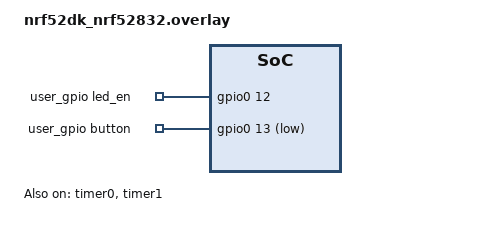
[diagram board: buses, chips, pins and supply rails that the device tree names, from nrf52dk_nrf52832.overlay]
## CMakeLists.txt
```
cmake_minimum_required(VERSION 3.20.0)
find_package(Zephyr REQUIRED HINTS $ENV{ZEPHYR_BASE})

project(nordic)

target_include_directories(app PRIVATE src src/drivers)

# Get all source and header files
file(GLOB_RECURSE SOURCES src/*.c src/drivers/*.c)
file(GLOB_RECURSE HEADERS src/*.h src/drivers/*.h)

# Add sources and header files to project
target_sources(app PRIVATE ${SOURCES})
target_sources(app PRIVATE ${HEADERS})
```

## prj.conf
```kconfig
#
# LOGGING
#
CONFIG_LOG=y

#
# PERIPHERALS
#
CONFIG_FPU=y
CONFIG_GPIO=y
CONFIG_I2C=y

#
# NRFX DRIVERS
#
CONFIG_NRFX_GPIOTE0=y
CONFIG_NRFX_PPI=y
CONFIG_NRFX_PWM1=y
CONFIG_NRFX_TIMER0=y
CONFIG_NRFX_TIMER1=y

#
# DEVICES
#

#
# SYSTEM
#
CONFIG_POWEROFF=y
```

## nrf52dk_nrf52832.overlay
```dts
// To get started, press Ctrl+Space to bring up the completion menu and view the available nodes.

// You can also use the buttons in the sidebar to perform actions on nodes.
// Actions currently available include:

// * Enabling / disabling the node
// * Adding the bus to a bus
// * Removing the node
// * Connecting ADC channels

// For more help, browse the DeviceTree documentation at https://docs.zephyrproject.org/latest/guides/dts/index.html
// You can also visit the nRF DeviceTree extension documentation at https://docs.nordicsemi.com/bundle/nrf-connect-vscode/page/guides/ncs_configure_app.html#devicetree-support-in-the-extension

&pwm_led0 {
	pwms = <&pwm0 0 PWM_KHZ(100) 0>;
};

/ {
	user_gpio: zephyr,user {
		led_en-gpios = <&gpio0 12 GPIO_PULL_DOWN>;
		button-gpios = <&gpio0 13 (GPIO_ACTIVE_LOW | GPIO_PULL_UP)>;
	};
};

&timer0 {
	status = "okay";
};

&timer1 {
	status = "okay";
};
```

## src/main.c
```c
/**
 * @file main.c
 * @author Ben Owen (ben@embeddedshark.com)
 * @brief Application entry file
 * 
 * @date 2024-10-20
 * 
 * @copyright Copyright (c) 2024
 * 
 */

#include "button.h"
#include "device.h"
#include "led.h"

#include <zephyr/kernel.h>
#include <zephyr/logging/log.h>
#include <nrfx_gpiote.h>

LOG_MODULE_REGISTER(MAIN, LOG_LEVEL_DBG);

/* Define task to handle button events */
#define BUTTON_THREAD_PRIORITY  4
K_THREAD_DEFINE(button_task_id, 1024, button_thread, NULL, NULL, NULL, BUTTON_THREAD_PRIORITY, 0, K_TICKS_FOREVER);  // Delay start to allow GPIO time to initialize

/**
 * @brief Application entry point
 * 
 * @return int 
 */
int main(void)
{
    /* Initialize peripherals */
    NRF_GPIO->DETECTMODE = GPIO_DETECTMODE_DETECTMODE_LDETECT;
    
    /* Get reset source */
    device_reset_src_t reset_src = device_get_reset_src();

    /* Initialize drivers */
    led_init();
    button_init();  // Needs to be last to enable all other wakeup sources before sleeping

    /* Start threads */
    k_thread_start(button_task_id);

    /* Put device to sleep if reset from flashing */
    if (reset_src == DEVICE_RESET_SRC_RESET_PIN)
    {
        device_poweroff();
    }

    return 0;
}
```

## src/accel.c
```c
/**
 * @file accel.c
 * @author Ben Owen (ben@embeddedshark.com)
 * @brief File containing setup for accelerometer
 * 
 * @date 2024-10-25
 * 
 * @copyright Copyright (c) 2024
 * 
 */

#include "accel.h"

#include "lis2dtw12.h"

#include <zephyr/device.h>
#include <zephyr/drivers/i2c.h>
#include <zephyr/logging/log.h>
#include <zephyr/sys/byteorder.h>
#include <zephyr/types.h>

LOG_MODULE_REGISTER(ACCEL, LOG_LEVEL_INF);

double accel_get_x(void)
{
    /* Read acceleration */
    int16_t accel_x = 0;
    lis2dtw12_reg_read(LIS2DTW12_OUT_X_L, &accel_x, 2);
    /* 14-bit = 0.244 mg/digit */
    double accel_x_converted = accel_x * 0.000244;

    return accel_x_converted;
}

double accel_get_y(void)
{
    /* Read acceleration */
    int16_t accel_y = 0;
    lis2dtw12_reg_read(LIS2DTW12_OUT_Y_L, &accel_y, 2);
    /* 14-bit = 0.244 mg/digit */
    double accel_y_converted = accel_y * 0.000244;

    return accel_y_converted;
}

double accel_get_z(void)
{
    /* Read acceleration */
    int16_t accel_z = 0;
    lis2dtw12_reg_read(LIS2DTW12_OUT_Z_L, &accel_z, 2);
    /* 14-bit = 0.244 mg/digit */
    double accel_z_converted = accel_z * 0.000244;

    return accel_z_converted;
}

int16_t accel_get_temp(void)
{
    /* Read temperature */
    int16_t temperature = 0;
    lis2dtw12_reg_read(LIS2DTW12_OUT_T_L, &temperature, 2);
    /* Convert temperature to celsius (integer, no decimals) */
    temperature >>= 8;  // 16 LSB per C, need to shift 4 additional since its 12-bit left-aligned
    temperature += 25;  // 0 LSB = 25 C
    
    return temperature;
}

void accel_init(void)
{
    /* Make sure device is responding */
    __ASSERT(lis2dtw12_get_device_id() == DEVICE_ID, "Acclerometer not responding on I2C bus");
    /* Initialize accelerometer with desired settings */
    lis2dtw12_init(CTRL1_ODR_25_HZ, CTRL1_MODE_HP, CTRL1_LP_MODE_2, CTRL6_BW_FILT_ODR_2, CTRL6_FS_2G, CTRL6_FDS, 0);
    /* Set INT1 pin configuration */
    lis2dtw12_reg_write(LIS2DTW12_CTRL4_INT1_PAD_CTRL, CTRL4_INT1_PAD_CTRL_INT1_WU);
    /* Set INT2 pin configuration */
    lis2dtw12_reg_write(LIS2DTW12_CTRL5_INT2_PAD_CTRL, CTRL5_INT2_PAD_CTRL_INT2_SLEEP_STATE | CTRL5_INT2_PAD_CTRL_INT2_SLEEP_CHG);
    /* Set wake up threshold */
    lis2dtw12_reg_write(LIS2DTW12_WAKE_UP_THS, WAKE_UP_THS_SLEEP_ON | (0b001000 & WAKE_UP_THS_WK_THS));  // should be 0.25 g
    /* Set wake up/sleep duration
        WAKE UP:
            At 25 Hz, each LSB = 0.04 seconds
            Maximum duration is 0b11 = 0.12 seconds
        SLEEP:
            At 25 Hz, each LSB = 20.48 seconds
            Maximum duration is 0b1111 ~= 300 seconds (5 minutes) */
    lis2dtw12_reg_write(LIS2DTW12_WAKE_UP_DUR, (0b01 & WAKE_UP_DUR_WAKE_DUR) | (0b1111 & WAKE_UP_DUR_SLEEP_DUR));  // should be 0.08 second wake up duration, 20.48 second sleep duration
    /* Set CTRL7 fields to enable interrupts and filter out gravity */
    lis2dtw12_reg_write(LIS2DTW12_CTRL7, CTRL7_INTERRUPTS_ENABLE | CTRL7_HP_REF_MODE);
    /* Allow device time to poll some data */
    k_msleep(100);
}
```

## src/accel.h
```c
/**
 * @file accel.h
 * @author Ben Owen (ben@embeddedshark.com)
 * @brief Header file for accel.c
 * 
 * @date 2024-10-25
 * 
 * @copyright Copyright (c) 2024 Embedded Shark, LLC
 * 
 */

#ifndef __ACCEL_H__
#define __ACCEL_H__

#include "stdint.h"

/**
 * FUNCTION DECLARATIONS
 */

/**
 * @brief Get acceleration in X-axis
 * 
 * @return double accleration (g)
 */
double accel_get_x(void);

/**
 * @brief Get acceleration in Y-axis
 * 
 * @return double accleration (g)
 */
double accel_get_y(void);

/**
 * @brief Get acceleration in Z-axis
 * 
 * @return double accleration (g)
 */
double accel_get_z(void);

/**
 * @brief Get temperature
 * 
 * @return int16_t temperature (celsius)
 */
int16_t accel_get_temp(void);

/**
 * @brief Initialize accelerometer
 * 
 */
void accel_init(void);

#endif  /* __ACCEL_H__ */
```

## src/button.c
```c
/**
 * @file button.c
 * @author your name (you@domain.com)
 * @brief File containing interface button logic
 * 
 * @date 2024-10-20
 * 
 * @copyright Copyright (c) 2024
 * 
 */

#include "button.h"

#include "device.h"
#include "led.h"

#include <zephyr/drivers/gpio.h>
#include <zephyr/kernel.h>
#include <zephyr/logging/log.h>

LOG_MODULE_REGISTER(BUTTON, LOG_LEVEL_INF);

/* GPIO */
static const struct gpio_dt_spec _button_dt = GPIO_DT_SPEC_GET(DT_NODELABEL(user_gpio), button_gpios);

const struct gpio_dt_spec * button_get_dt_spec(void)
{
    return &_button_dt;
}

void button_thread(void)
{
    /* The button buffer works by shifting left and ORing the button state
        If the buffer is all 1s, then a long press occurred
        If the buffer is some 1s followed by a 0, then a press was released */
    uint32_t button_buffer = 0;

    while (1)
    {
        /* Place button state into buffer */
        button_buffer = (button_buffer << 1) | gpio_pin_get_dt(&_button_dt);
        /* Check for button events */
        if (button_buffer == 0x7FFFFFFF)
        {
            /* Long press occurred
                We use 0x7FFFFFFF so that it won't constantly detect long presses if still held */
            LOG_DBG("Long press");
            if (device_get_state() == DEVICE_STATE_POWEROFF)
            {
                /* Wake up device */
                device_wakeup();
            }
            else if (device_get_state() == DEVICE_STATE_RUN)
            {
                /* Power off device if running */
                device_poweroff();
            }
        }
        else if (button_buffer == 0xFFFFFFFE)
        {
            /* Long press released */
            LOG_DBG("Long press released");
        }
        else if ((button_buffer & 0x3) == 0x2)
        {
            /* Short press released */
            LOG_DBG("Short press released");
            if (device_get_state() == DEVICE_STATE_POWEROFF)
            {
                /* Button not held long enough, go back to sleep */
                device_poweroff();
            }
            else if (device_get_state() == DEVICE_STATE_RUN)
            {
                /* Toggle LED pattern */
                led_toggle_pattern();
            }
        }

        /* Delay until next poll interval */
        k_msleep(1000 / BUTTON_POLL_HZ);
    }
}

void button_init()
{
    int err;

    /* GPIO config */
    /* Initialize GPIO */
	__ASSERT(device_is_ready(_button_dt.port), "Button port not ready");
    /* Configure button as input pin */
	err = gpio_pin_configure_dt(&_button_dt, GPIO_INPUT);
	__ASSERT(err == 0, "Error configuring button as input");
}
```

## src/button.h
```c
/**
 * @file button.h
 * @author Ben Owen (ben@embeddedshark.com)
 * @brief Header file for button.c
 * 
 * @date 2024-10-20
 * 
 * @copyright Copyright (c) 2024
 * 
 */

#ifndef __BUTTON_H__
#define __BUTTON_H__

#define BUTTON_GPIOTE_INSTANCE      0
#define BUTTON_TIMER_INSTANCE       1

#define BUTTON_POLL_HZ              20

/**
 * @brief Get the button GPIO DT spec
 * 
 * @return struct gpio_dt_spec* 
 */
const struct gpio_dt_spec * button_get_dt_spec(void);

/**
 * @brief This thread reads button inputs and handles short/long presses
 * 
 */
void button_thread(void);

/**
 * @brief Initialize all peripherals for interface button
 * 
 */
void button_init(void);

#endif  /* __BUTTON_H__ */
```

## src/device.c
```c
/**
 * @file device.c
 * @author Ben Owen (ben@embeddedshark.com)
 * @brief File containing global device-level functions
 *          Also contains global device-level state variables
 * 
 * @date 2024-10-21
 * 
 * @copyright Copyright (c) 2024
 * 
 */

#include "device.h"

#include "button.h"
#include "led.h"

#include <zephyr/drivers/gpio.h>
#include <zephyr/kernel.h>
#include <zephyr/logging/log.h>
#include <zephyr/sys/poweroff.h>

LOG_MODULE_REGISTER(DEVICE, LOG_LEVEL_INF);

/**
 * LOCAL VARIABLES
 */

static device_state_t _device_state;

/**
 * FUNCTION DEFINITIONS
 */

device_state_t device_get_state(void)
{
    return _device_state;
}

void device_set_state(device_state_t new_state)
{
    _device_state = new_state;
}

void device_wakeup(void)
{
    /* Set device state */
    device_set_state(DEVICE_STATE_RUN);
    /* Set boot LED pattern */
    led_set_pattern(LED_PATTERN_PULSE);
}

void device_poweroff()
{
    int err;

    /* Change device state */
    device_set_state(DEVICE_STATE_POWEROFF);
    /* Clear LED */
    led_set_pattern(LED_PATTERN_OFF);
    /* Wait until button released */
    while (gpio_pin_get_dt(button_get_dt_spec()));
    k_msleep(250);  // delay a small period for button bouncing
    /* Configure interrupt for button (wakeup source) */
    err = gpio_pin_interrupt_configure_dt(button_get_dt_spec(), GPIO_INT_LEVEL_ACTIVE);
    __ASSERT(err == 0, "Error changing button interrupt");
    /* Clear LATCH register */
    NRF_GPIO->LATCH = NRF_GPIO->LATCH;
    /* Put microcontroller to sleep */
    LOG_WRN("Powering device off");
    sys_poweroff();
}

device_reset_src_t device_get_reset_src(void)
{
    /* Get reset source */
    uint32_t reset_src = NRF_POWER->RESETREAS;
    /* Clear reset source register */
    NRF_POWER->RESETREAS = 0xFFFFFFFF;

    /* Determine reset reason */
    if (reset_src & POWER_RESETREAS_OFF_Msk)
    {
        return DEVICE_RESET_SRC_GPIO_WAKEUP;
    }
    else if (reset_src & POWER_RESETREAS_LOCKUP_Msk)
    {
        return DEVICE_RESET_SRC_CPU_LOCKUP;
    }
    else if (reset_src & POWER_RESETREAS_SREQ_Msk)
    {
        return DEVICE_RESET_SRC_SOFT_RESET;
    }
    else if (reset_src & POWER_RESETREAS_DOG_Msk)
    {
        return DEVICE_RESET_SRC_WATCHDOG;
    }
    else if (reset_src & POWER_RESETREAS_RESETPIN_Msk)
    {
        return DEVICE_RESET_SRC_RESET_PIN;
    }
    else
    {
        return DEVICE_RESET_SRC_OTHER;
    }
}
```

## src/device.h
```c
/**
 * @file device.h
 * @author Ben Owen (ben@embeddedshark.com)
 * @brief Header file for device.c
 * 
 * @date 2024-10-21
 * 
 * @copyright Copyright (c) 2024
 * 
 */

#ifndef __DEVICE_H__
#define __DEVICE_H__

#include <zephyr/drivers/gpio.h>

/* ENUMERATION DEFINITIONS */

typedef enum
{
    DEVICE_STATE_POWEROFF,
    DEVICE_STATE_WAKEUP,
    DEVICE_STATE_RUN,
}
device_state_t;

typedef enum
{
    DEVICE_RESET_SRC_GPIO_WAKEUP,
    DEVICE_RESET_SRC_CPU_LOCKUP,
    DEVICE_RESET_SRC_SOFT_RESET,
    DEVICE_RESET_SRC_WATCHDOG,
    DEVICE_RESET_SRC_RESET_PIN,
    DEVICE_RESET_SRC_OTHER,
}
device_reset_src_t;

/**
 * FUNCTION DECLARATIONS
 */

/**
 * @brief Get the device state
 * 
 */
device_state_t device_get_state(void);

/**
 * @brief Change the device state
 * 
 * @param new_state 
 */
void device_set_state(device_state_t new_state);

/**
 * @brief Device initialization when waking from sleep
 * 
 */
void device_wakeup(void);

/**
 * @brief Turn the device off
 *          Handles cleanup before shutting off
 * 
 */
void device_poweroff();

/**
 * @brief Get the device wakeup reason
 * 
 * @return device_reset_src_t 
 */
device_reset_src_t device_get_reset_src(void);

#endif  /* __DEVICE_H__ */
```

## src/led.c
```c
/**
 * @file led.c
 * @author Ben Owen (ben@embeddedshark.com)
 * @brief File to initialize and change LED blink modes
 * 
 * @date 2024-10-20
 * 
 * @copyright Copyright (c) 2024
 * 
 */

#include "led.h"

#include <nrfx_gpiote.h>
#include <nrfx_ppi.h>
#include <nrfx_pwm.h>
#include <nrfx_timer.h>

#include <zephyr/logging/log.h>

#if (LED_TIMER_INSTANCE == 0)
#define LED_TIMER_IRQN       TIMER0_IRQn
#elif (LED_TIMER_INSTANCE == 1)
#define LED_TIMER_IRQN       TIMER1_IRQn
#elif (LED_TIMER_INSTANCE == 2)
#define LED_TIMER_IRQN       TIMER2_IRQn
#elif (LED_TIMER_INSTANCE == 3)
#define LED_TIMER_IRQN       TIMER3_IRQn
#elif (LED_TIMER_INSTANCE == 4)
#define LED_TIMER_IRQN       TIMER4_IRQn
#endif

LOG_MODULE_REGISTER(LED, LOG_LEVEL_INF);

/**
 * @brief Pattern for constant max brightness
 * 
 */
nrf_pwm_values_common_t _pwm_pattern_on[] =
{
    100,
};
nrf_pwm_sequence_t _pwm_seq_on =
{
    .values = { _pwm_pattern_on },
    .length = NRFX_ARRAY_SIZE(_pwm_pattern_on),
    .repeats = 10,  // 10 ticks per value
    .end_delay = 0  // no delay between repeats
};

/**
 * @brief Pattern for constant medium brightness
 * 
 */
nrf_pwm_values_common_t _pwm_pattern_mid[] =
{
    600,
};
nrf_pwm_sequence_t _pwm_seq_mid =
{
    .values = { _pwm_pattern_mid },
    .length = NRFX_ARRAY_SIZE(_pwm_pattern_mid),
    .repeats = 10,  // 10 ticks per value
    .end_delay = 0  // no delay between repeats
};

/**
 * @brief Pattern for constant low brightness
 * 
 */
nrf_pwm_values_common_t _pwm_pattern_dim[] =
{
    1000,
};
nrf_pwm_sequence_t _pwm_seq_dim =
{
    .values = { _pwm_pattern_dim },
    .length = NRFX_ARRAY_SIZE(_pwm_pattern_dim),
    .repeats = 10,  // 10 ticks per value
    .end_delay = 0  // no delay between repeats
};

/**
 * @brief Pattern for dim blinking
 * 
 */
nrf_pwm_values_common_t _pwm_pattern_dim_blink[] =
{
    600,  1000, 1000, 1000, 1000, 1000, 1000, 1000, 1000, 600,
    1000, 1000, 1000, 1000, 1000, 1000, 1000, 1000, 1000, 1000,
    1000, 1000, 1000, 1000, 1000, 1000, 1000, 1000, 1000, 1000,
    1000, 1000, 1000, 1000, 1000, 1000, 1000, 1000, 1000, 1000,
    1000, 1000, 1000, 1000, 1000, 1000, 1000, 1000, 1000, 1000,
    1000, 1000, 1000, 1000, 1000, 1000, 1000, 1000, 1000, 1000,
    1000, 1000, 1000, 1000, 1000, 1000, 1000, 1000, 1000, 1000,
    1000, 1000, 1000, 1000, 1000, 1000, 1000, 1000, 1000, 1000,
    1000, 1000, 1000, 1000, 1000, 1000, 1000, 1000, 1000, 1000,
    1000, 1000, 1000, 1000, 1000, 1000, 1000, 1000, 1000, 1000,
};
nrf_pwm_sequence_t _pwm_seq_dim_blink =
{
    .values = { _pwm_pattern_dim_blink },
    .length = NRFX_ARRAY_SIZE(_pwm_pattern_dim_blink),
    .repeats = 10,  // 10 ticks per value
    .end_delay = 0  // no delay between repeats
};

/**
 * @brief Pattern for pulsing
 * 
 */
nrf_pwm_values_common_t _pwm_pattern_pulse[] =
{
    990,  980,  970,  960,  950,  940,  930,  920,  910,  900,
    890,  880,  870,  860,  850,  840,  830,  820,  810,  800,
    790,  780,  770,  760,  750,  740,  730,  720,  710,  700,
    690,  680,  670,  660,  650,  640,  630,  620,  610,  600,
    590,  580,  570,  560,  550,  540,  530,  520,  510,  500,
    500,  500,  500,  500,  500,  500,  500,  500,  500,  500,
    500,  510,  520,  530,  540,  550,  560,  570,  580,  590,
    600,  610,  620,  630,  640,  650,  660,  670,  680,  690,
    700,  710,  720,  730,  740,  750,  760,  770,  780,  790,
    800,  810,  820,  830,  840,  850,  860,  870,  880,  890,
    900,  910,  920,  930,  940,  950,  960,  970,  980,  990,
    1000, 1000, 1000, 1000, 1000, 1000, 1000, 1000, 1000, 1000,
};
nrf_pwm_sequence_t _pwm_seq_pulse =
{
    .values = { _pwm_pattern_pulse },
    .length = NRFX_ARRAY_SIZE(_pwm_pattern_pulse),
    .repeats = 25,  // 10 ticks per value
    .end_delay = 1000  // no delay between repeats
};

/* GPIO */
static nrfx_gpiote_t _gpiote = NRFX_GPIOTE_INSTANCE(LED_GPIOTE_INSTANCE);
#define LED_EN_PIN DT_GPIO_PIN(DT_NODELABEL(user_gpio), led_en_gpios)

/* Timer */
static nrfx_timer_t _timer_led = NRFX_TIMER_INSTANCE(LED_TIMER_INSTANCE);

/* PPI */
nrf_ppi_channel_t _ppi_first_blink_start_ch;
nrf_ppi_channel_t _ppi_first_blink_end_ch;
nrf_ppi_channel_t _ppi_second_blink_start_ch;
nrf_ppi_channel_t _ppi_second_blink_end_ch;

/* PWM */
static nrfx_pwm_t _pwm_led = NRFX_PWM_INSTANCE(LED_PWM_INSTANCE);
#define LED_PWM_PIN 17

/* Other locals */
led_pattern_t _current_pattern;

void led_init(void)
{
    nrfx_err_t err;

    /* GPIO config */
    /* Initialize GPIO */
    err = nrfx_gpiote_init(&_gpiote, NRFX_GPIOTE_DEFAULT_CONFIG_IRQ_PRIORITY);
    NRFX_ASSERT(err == NRFX_SUCCESS);
    /* Generate output configurations */
    nrfx_gpiote_output_config_t _led_en_config = NRFX_GPIOTE_DEFAULT_OUTPUT_CONFIG;
    /* Allocate GPIOTE channels for tasks */
    uint8_t _gpiote_led_en_ch;
    err = nrfx_gpiote_channel_alloc(&_gpiote, &_gpiote_led_en_ch);
    NRFX_ASSERT(err == NRFX_SUCCESS);
    /* Create tasks */
    nrfx_gpiote_task_config_t _led_en_task =
    {
        .task_ch = _gpiote_led_en_ch,
        .polarity = NRF_GPIOTE_POLARITY_TOGGLE,
        .init_val = NRF_GPIOTE_INITIAL_VALUE_LOW,
    };
    /* Configure LED enable pin with defined configurations */
    err = nrfx_gpiote_output_configure(&_gpiote, LED_EN_PIN, &_led_en_config, &_led_en_task);
    NRFX_ASSERT(err == NRFX_SUCCESS);
    /* Enable GPIOTE task */
    nrfx_gpiote_out_task_enable(&_gpiote, LED_EN_PIN);

    /* Timer config */
    /* Configure timer parameters */
    nrfx_timer_config_t _timer_led_config =
    {
        .frequency          = NRFX_MHZ_TO_HZ(1),
        .mode               = NRF_TIMER_MODE_TIMER,
        .bit_width          = NRF_TIMER_BIT_WIDTH_32,
        .interrupt_priority = NRFX_TIMER_DEFAULT_CONFIG_IRQ_PRIORITY,
        .p_context          = NULL,
    };
    /* Initialize timer */
    err = nrfx_timer_init(&_timer_led, &_timer_led_config, NULL);
    NRFX_ASSERT(err == NRFX_SUCCESS);
    /* Needed to handle timer compare interrupts */
    IRQ_CONNECT(LED_TIMER_IRQN, IRQ_PRIO_LOWEST, NRFX_TIMER_INST_HANDLER_GET(LED_TIMER_INSTANCE), NULL, 0);

    /* PWM config */
    /* Initialize PWM */
    nrfx_pwm_config_t config = NRFX_PWM_DEFAULT_CONFIG(LED_PWM_PIN, NRF_PWM_PIN_NOT_CONNECTED, NRF_PWM_PIN_NOT_CONNECTED, NRF_PWM_PIN_NOT_CONNECTED);
    err = nrfx_pwm_init(&_pwm_led, &config, NULL, &_pwm_led);
    NRFX_ASSERT(err == NRFX_SUCCESS);
    /* Handle PWM interrupt */
    IRQ_CONNECT(NRFX_IRQ_NUMBER_GET(NRF_PWM_INST_GET(LED_PWM_INSTANCE)), IRQ_PRIO_LOWEST, NRFX_PWM_INST_HANDLER_GET(LED_PWM_INSTANCE), 0, 0);

    /* PPI config */
    /* Allocate PPI channels */
    err = nrfx_ppi_channel_alloc(&_ppi_first_blink_start_ch);
    NRFX_ASSERT(err == NRFX_SUCCESS);
    err = nrfx_ppi_channel_alloc(&_ppi_first_blink_end_ch);
    NRFX_ASSERT(err == NRFX_SUCCESS);
    err = nrfx_ppi_channel_alloc(&_ppi_second_blink_start_ch);
    NRFX_ASSERT(err == NRFX_SUCCESS);
    err = nrfx_ppi_channel_alloc(&_ppi_second_blink_end_ch);
    NRFX_ASSERT(err == NRFX_SUCCESS);
}

void led_set_pattern(led_pattern_t pattern)
{
    nrfx_err_t err;
    /* Disable LED driver while setting up new pattern */
    nrfx_gpiote_clr_task_trigger(&_gpiote, LED_EN_PIN);
    /* Disable timer */
    nrfx_timer_disable(&_timer_led);
    nrfx_timer_clear(&_timer_led);
    /* Disable PPI channels */
    err = nrfx_ppi_channel_disable(_ppi_first_blink_start_ch);
    NRFX_ASSERT(err == NRFX_SUCCESS);
    err = nrfx_ppi_channel_disable(_ppi_first_blink_end_ch);
    NRFX_ASSERT(err == NRFX_SUCCESS);
    err = nrfx_ppi_channel_disable(_ppi_second_blink_start_ch);
    NRFX_ASSERT(err == NRFX_SUCCESS);
    err = nrfx_ppi_channel_disable(_ppi_second_blink_end_ch);
    NRFX_ASSERT(err == NRFX_SUCCESS);
    /* Disable PWM sequence */
    nrfx_pwm_stop(&_pwm_led, true);
    /* Store new pattern */
    _current_pattern = pattern;

    /* Set up pattern */
    switch (pattern)
    {
        case (LED_PATTERN_BRIGHT_BLINK):
        {
            /* Pattern is 2 quick blinks, otherwise off */
            /* Set timer compare channels */
            nrfx_timer_compare(&_timer_led, NRF_TIMER_CC_CHANNEL0, nrfx_timer_ms_to_ticks(&_timer_led, 10), false);
            nrfx_timer_compare(&_timer_led, NRF_TIMER_CC_CHANNEL1, nrfx_timer_ms_to_ticks(&_timer_led, 90), false);
            nrfx_timer_compare(&_timer_led, NRF_TIMER_CC_CHANNEL2, nrfx_timer_ms_to_ticks(&_timer_led, 100), false);
            nrfx_timer_extended_compare(&_timer_led, NRF_TIMER_CC_CHANNEL3, nrfx_timer_ms_to_ticks(&_timer_led, 1000), NRF_TIMER_SHORT_COMPARE3_CLEAR_MASK, false);
            /* Assign PPI channels to set/clear LED enable pin */
            err = nrfx_ppi_channel_assign(_ppi_first_blink_start_ch, nrfx_timer_event_address_get(&_timer_led, NRF_TIMER_EVENT_COMPARE3), nrfx_gpiote_set_task_address_get(&_gpiote, LED_EN_PIN));
            NRFX_ASSERT(err == NRFX_SUCCESS);
            err = nrfx_ppi_channel_assign(_ppi_first_blink_end_ch, nrfx_timer_event_address_get(&_timer_led, NRF_TIMER_EVENT_COMPARE0), nrfx_gpiote_clr_task_address_get(&_gpiote, LED_EN_PIN));
            NRFX_ASSERT(err == NRFX_SUCCESS);
            err = nrfx_ppi_channel_assign(_ppi_second_blink_start_ch, nrfx_timer_event_address_get(&_timer_led, NRF_TIMER_EVENT_COMPARE1), nrfx_gpiote_set_task_address_get(&_gpiote, LED_EN_PIN));
            NRFX_ASSERT(err == NRFX_SUCCESS);
            err = nrfx_ppi_channel_assign(_ppi_second_blink_end_ch, nrfx_timer_event_address_get(&_timer_led, NRF_TIMER_EVENT_COMPARE2), nrfx_gpiote_clr_task_address_get(&_gpiote, LED_EN_PIN));
            NRFX_ASSERT(err == NRFX_SUCCESS);
            /* Enable PPI channels */
            err = nrfx_ppi_channel_enable(_ppi_first_blink_start_ch);
            NRFX_ASSERT(err == NRFX_SUCCESS);
            err = nrfx_ppi_channel_enable(_ppi_first_blink_end_ch);
            NRFX_ASSERT(err == NRFX_SUCCESS);
            err = nrfx_ppi_channel_enable(_ppi_second_blink_start_ch);
            NRFX_ASSERT(err == NRFX_SUCCESS);
            err = nrfx_ppi_channel_enable(_ppi_second_blink_end_ch);
            NRFX_ASSERT(err == NRFX_SUCCESS);
            /* Set PWM sequence to max brightness (will control blinks with enable GPIO) */
            nrfx_pwm_simple_playback(&_pwm_led, &_pwm_seq_on, 1, NRFX_PWM_FLAG_LOOP);
            /* Start timer */
            nrfx_timer_enable(&_timer_led);
            break;
        }

        case (LED_PATTERN_DIM_BLINK):
        {
            /* Pattern is 2 quick blinks, otherwise dim */
            /* Enable LED driver constantly (PWM pattern will handle blinks) */
            nrfx_gpiote_set_task_trigger(&_gpiote, LED_EN_PIN);
            /* Set PWM sequence to dim blink pattern */
            nrfx_pwm_simple_playback(&_pwm_led, &_pwm_seq_dim_blink, 1, NRFX_PWM_FLAG_LOOP);
            break;
        }

        case (LED_PATTERN_BRIGHT_SOLID):
        {
            /* Pattern is solid bright */
            /* Enable LED driver constantly (PWM pattern will handle brightness) */
            nrfx_gpiote_set_task_trigger(&_gpiote, LED_EN_PIN);
            /* Set PWM sequence to bright solid pattern */
            nrfx_pwm_simple_playback(&_pwm_led, &_pwm_seq_mid, 1, NRFX_PWM_FLAG_LOOP);
            break;
        }

        case (LED_PATTERN_DIM_SOLID):
        {
            /* Pattern is solid dim */
            /* Enable LED driver constantly (PWM pattern will handle brightness) */
            nrfx_gpiote_set_task_trigger(&_gpiote, LED_EN_PIN);
            /* Set PWM sequence to dim solid pattern */
            nrfx_pwm_simple_playback(&_pwm_led, &_pwm_seq_dim, 1, NRFX_PWM_FLAG_LOOP);
            break;
        }

        case (LED_PATTERN_PULSE):
        {
            /* Pattern is pulse from dim to bright to dim */
            /* Enable LED driver constantly (PWM pattern will handle pulse) */
            nrfx_gpiote_set_task_trigger(&_gpiote, LED_EN_PIN);
            /* Set PWM sequence to pulse pattern */
            nrfx_pwm_simple_playback(&_pwm_led, &_pwm_seq_pulse, 1, NRFX_PWM_FLAG_LOOP);
            break;
        }

        case (LED_PATTERN_OFF):
        {
            /* Pattern is off */
            /* Disable LED driver */
            nrfx_gpiote_clr_task_trigger(&_gpiote, LED_EN_PIN);
            // /* Set PWM sequence to blink pattern */
            // nrfx_pwm_simple_playback(&_pwm_led, &_pwm_seq_mid, 1, NRFX_PWM_FLAG_LOOP);
            break;
        }

        default:
        {
            /* Invalid pattern */
            NRFX_ASSERT(0);
            break;
        }
    }
}

void led_toggle_pattern(void)
{
    _current_pattern = (_current_pattern + 1) % LED_PATTERN_NUM_PATTERNS;
    led_set_pattern(_current_pattern);
}
```

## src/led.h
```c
/**
 * @file led.h
 * @author Ben Owen (ben@embeddedshark.com)
 * @brief Header file for led.c
 * 
 * @date 2024-10-20
 * 
 * @copyright Copyright (c) 2024
 * 
 */

#ifndef __LED_H__
#define __LED_H__

#define LED_GPIOTE_INSTANCE 0
#define LED_PWM_INSTANCE    1
#define LED_TIMER_INSTANCE  0

typedef enum
{
    LED_PATTERN_BRIGHT_BLINK    = 0,
    LED_PATTERN_DIM_BLINK       = 1,
    LED_PATTERN_BRIGHT_SOLID    = 2,
    LED_PATTERN_DIM_SOLID       = 3,
    LED_PATTERN_PULSE           = 4,
    LED_PATTERN_NUM_PATTERNS,   // TOTAL NUMBER OF PATTERNS TO CYCLE
    LED_PATTERN_OFF,            // WILL NOT CYCLE TO OFF
}
led_pattern_t;

#endif  /* __LED_H__ */

/**
 * @brief Initialize all peripherals for LED control
 * 
 */
void led_init(void);

/**
 * @brief Set blink pattern of LED
 * 
 * @param pattern 
 */
void led_set_pattern(led_pattern_t pattern);

/**
 * @brief Toggle blink pattern (cycle through all patterns)
 * 
 */
void led_toggle_pattern(void);
```

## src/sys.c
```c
/**
 * @file sys.c
 * @author Ben Owen (ben@embeddedshark.com)
 * @brief File containing global system-level functions
 *          Also contains global system-level state variables
 * 
 * @date 2024-10-21
 * 
 * @copyright Copyright (c) 2024
 * 
 */

#include "sys.h"

#include "button.h"
#include "led.h"

#include <nrfx_gpiote.h>
#include <nrfx_timer.h>

#include <zephyr/drivers/gpio.h>
#include <zephyr/kernel.h>
#include <zephyr/logging/log.h>
#include <zephyr/sys/poweroff.h>

LOG_MODULE_REGISTER(SYS, LOG_LEVEL_INF);

/**
 * LOCAL VARIABLES
 */

sys_state_t sys_state = SYS_STATE_POWEROFF;

/**
 * FUNCTION DEFINITIONS
 */

void sys_power_off(const struct gpio_dt_spec * button_dt)
{
    nrfx_err_t err;

    // TODO: Turn off accelerometer - setting CTRL1 to 0x0000 will put device into power-down mode
    /* Clear LED */
    led_set_pattern(LED_PATTERN_OFF);
    /* Wait until button released */
    while (gpio_pin_get_dt(button_dt));
    k_msleep(250);  // delay a small period for button bouncing
    /* Configure interrupt for button (wakeup source) */
    err = gpio_pin_interrupt_configure_dt(button_dt, GPIO_INT_LEVEL_ACTIVE);
    NRFX_ASSERT(err == 0);
    /* Put microcontroller to sleep */
    LOG_WRN("Powering system off");
    sys_poweroff();
}

sys_reset_src_t sys_get_reset_src(void)
{
    /* Get reset source */
    uint32_t reset_src = NRF_POWER->RESETREAS;
    /* Clear reset source register */
    NRF_POWER->RESETREAS = 0xFFFFFFFF;

    /* Determine reset reason */
    if (reset_src & POWER_RESETREAS_OFF_Msk)
    {
        return SYS_RESET_SRC_GPIO_WAKEUP;
    }
    else if (reset_src & POWER_RESETREAS_LOCKUP_Msk)
    {
        return SYS_RESET_SRC_CPU_LOCKUP;
    }
    else if (reset_src & POWER_RESETREAS_SREQ_Msk)
    {
        return SYS_RESET_SRC_SOFT_RESET;
    }
    else if (reset_src & POWER_RESETREAS_DOG_Msk)
    {
        return SYS_RESET_SRC_WATCHDOG;
    }
    else if (reset_src & POWER_RESETREAS_RESETPIN_Msk)
    {
        return SYS_RESET_SRC_RESET_PIN;
    }
    else
    {
        return SYS_RESET_SRC_OTHER;
    }
}
```

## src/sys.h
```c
/**
 * @file sys.h
 * @author Ben Owen (ben@embeddedshark.com)
 * @brief Header file for sys.c
 * 
 * @date 2024-10-21
 * 
 * @copyright Copyright (c) 2024
 * 
 */

#ifndef __SYS_H__
#define __SYS_H__

#include <zephyr/drivers/gpio.h>

/* ENUMERATION DEFINITIONS */

typedef enum
{
    SYS_STATE_POWEROFF,
    SYS_STATE_WAKEUP,
    SYS_STATE_RUN,
}
sys_state_t;

typedef enum
{
    SYS_RESET_SRC_GPIO_WAKEUP,
    SYS_RESET_SRC_CPU_LOCKUP,
    SYS_RESET_SRC_SOFT_RESET,
    SYS_RESET_SRC_WATCHDOG,
    SYS_RESET_SRC_RESET_PIN,
    SYS_RESET_SRC_OTHER,
}
sys_reset_src_t;

/**
 * LOCAL VARIABLES
 */

extern sys_state_t sys_state;

/**
 * FUNCTION DECLARATIONS
 */

/**
 * @brief Turn the system off
 *          Handles cleanup before shutting off
 * 
 * @param button_dt 
 */
void sys_power_off(const struct gpio_dt_spec * button_dt);

/**
 * @brief Get the system wakeup reason
 * 
 * @return sys_reset_src_t 
 */
sys_reset_src_t sys_get_reset_src(void);

#endif  /* __SYS_H__ */
```
